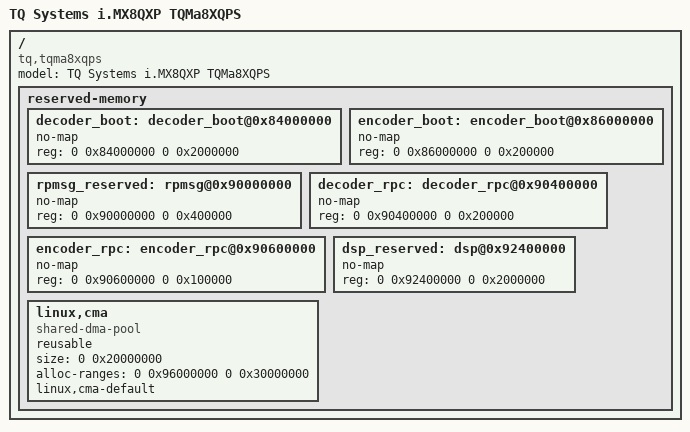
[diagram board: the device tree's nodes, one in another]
/*
 * Copyright 2018 - 2019 TQ Systems GmbH
 *
 * This program is free software; you can redistribute it and/or
 * modify it under the terms of the GNU General Public License
 * as published by the Free Software Foundation; either version 2
 * of the License, or (at your option) any later version.
 *
 * This program is distributed in the hope that it will be useful,
 * but WITHOUT ANY WARRANTY; without even the implied warranty of
 * MERCHANTABILITY or FITNESS FOR A PARTICULAR PURPOSE.  See the
 * GNU General Public License for more details.
 */

#include "fsl-imx8qxp.dtsi"
#include "tqma8xxs-common.dtsi"

/delete-node/ &decoder_boot;
/delete-node/ &encoder_boot;
/delete-node/ &decoder_rpc;
/delete-node/ &encoder_rpc;
/delete-node/ &dsp_reserved;
/delete-node/ &rpmsg_reserved;

/ {
	model = "TQ Systems i.MX8QXP TQMa8XQPS";
	compatible = "tq,tqma8xqps", "fsl,imx8qxp";

	reserved-memory {
		/*
		 * reserved-memory layout
		 * 0x8800_0000 ~ 0x8FFF_FFFF is reserved for M4
		 * Shouldn't be used at A core and Linux side.
		 *
		 */
		decoder_boot: decoder_boot@0x84000000 {
			no-map;
			reg = <0 0x84000000 0 0x2000000>;
		};
		encoder_boot: encoder_boot@0x86000000 {
			no-map;
			reg = <0 0x86000000 0 0x200000>;
		};
		rpmsg_reserved: rpmsg@0x90000000 {
			no-map;
			reg = <0 0x90000000 0 0x400000>;
		};
		decoder_rpc: decoder_rpc@0x90400000 {
			no-map;
			reg = <0 0x90400000 0 0x200000>;
		};
		encoder_rpc: encoder_rpc@0x90600000 {
			no-map;
			reg = <0 0x90600000 0 0x100000>;
		};
		dsp_reserved: dsp@0x92400000 {
			no-map;
			reg = <0 0x92400000 0 0x2000000>;
		};

		/*
		 * global autoconfigured region for contiguous allocations
		 * decrease CMA, may not exceed memory size and region
		 */
		linux,cma {
			compatible = "shared-dma-pool";
			reusable;
			size = <0 0x20000000>;
			alloc-ranges = <0 0x96000000 0 0x30000000>;
			linux,cma-default;
		};
	};
};
